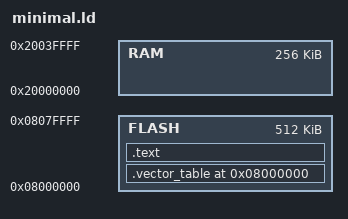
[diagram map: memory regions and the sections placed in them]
/* NUCLEO-U545RE-Q narrow smoke linker script: 512 KiB flash / 256 KiB SRAM. */
MEMORY
{
  FLASH : ORIGIN = 0x08000000, LENGTH = 512K
  RAM : ORIGIN = 0x20000000, LENGTH = 256K
}

ENTRY(Reset)

SECTIONS
{
  .vector_table 0x08000000 :
  {
    LONG(0x20040000); /* Initial SP at the top of the exposed 256 KiB SRAM. */
    LONG(Reset + 1);  /* Reset handler (Thumb). */
  } > FLASH

  .text :
  {
    *(.text*)
    *(.rodata*)
  } > FLASH

  /DISCARD/ :
  {
    *(.ARM.exidx*)
    *(.note.gnu.build-id*)
  }
}
